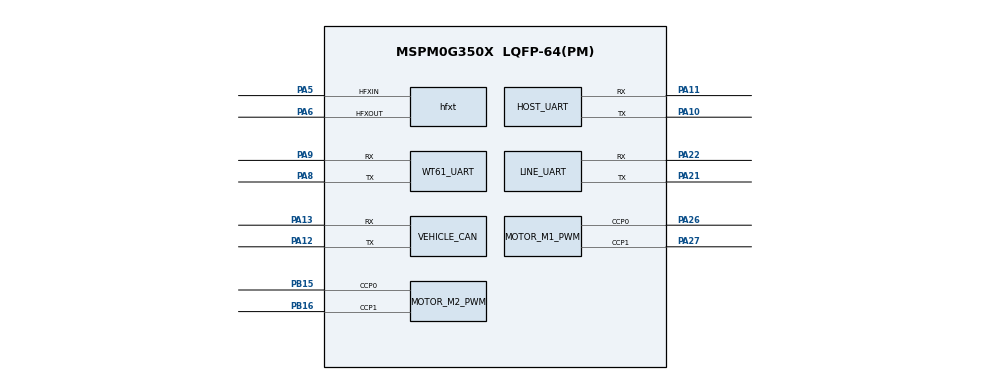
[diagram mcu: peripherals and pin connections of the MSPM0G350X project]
/**
 * MSPM0G3507 project pin/peripheral configuration (v0.3.0 - CAN加速度版)
 *
 * SysConfig 统一管理两路电机：
 *   M1 = TIMG7, PA26/PA27
 *   M2 = TIMG8, PB15/PB16
 * 避免第二路手写寄存器初始化与 SDK/SysConfig 生成配置不一致。
 * 两路编码器 (PB0-PB3) 由 SysConfig 配置成双边沿 GPIO 中断输入，
 * 避免主循环轮询速度不稳定时漏计高速脉冲。
 * CANFD0工作在经典CAN模式：PA12(TX)/PA13(RX)，500 kbps。
 * CANCLK使用核心板PA5/PA6上的40 MHz外部晶振，CPU仍保持32 MHz。
 *
 * @cliArgs --device "MSPM0G350X" --part "Default" --package "LQFP-64(PM)" --product "mspm0_sdk@2.11.00.07"
 * @versions {"tool":"1.26.2+4477"}
 */

const GPIO       = scripting.addModule("/ti/driverlib/GPIO", {}, false);
const BUZZER     = GPIO.addInstance();
const SPEED_KEY  = GPIO.addInstance();
const MODE_KEY   = GPIO.addInstance();
const LCD        = GPIO.addInstance();
const ENCODER_IO = GPIO.addInstance();
const UART       = scripting.addModule("/ti/driverlib/UART", {}, false);
const HOST_UART  = UART.addInstance();
const WT61_UART  = UART.addInstance();
const LINE_UART  = UART.addInstance();
const MCAN       = scripting.addModule("/ti/driverlib/MCAN", {}, false);
const VEHICLE_CAN = MCAN.addInstance();
const PWM        = scripting.addModule("/ti/driverlib/PWM", {}, false);
const MOTOR_M1_PWM = PWM.addInstance();
const MOTOR_M2_PWM = PWM.addInstance();
const SYSCTL     = scripting.addModule("/ti/driverlib/SYSCTL");
const Board      = scripting.addModule("/ti/driverlib/Board", {}, false);

/*
 * 天猛星核心板40 MHz外部晶振仅供HFCLK/CANCLK使用。
 * MCLK仍使用32 MHz SYSOSC，因此现有PWM周期和软件延时基准不改变。
 */
const hfxMux = system.clockTree["EXHFMUX"];
hfxMux.inputSelect = "EXHFMUX_XTAL";
const hfxExt = system.clockTree["HFCLKEXT"];
hfxExt.inputFreq = 40;
const hfxt = system.clockTree["HFXT"];
hfxt.enable = true;
hfxt.HFXTStartup = 10;
hfxt.HFCLKMonitor = true;
hfxt.inputFreq = 40;
hfxt.peripheral.$assign = "SYSCTL";
hfxt.peripheral.hfxInPin.$assign = "PA5";
hfxt.peripheral.hfxOutPin.$assign = "PA6";

/* Optional buzzer already present on the core board. */
BUZZER.port                                  = "PORTA";
BUZZER.$name                                 = "BUZZER";
BUZZER.associatedPins[0].assignedPin         = "7";
BUZZER.associatedPins[0].assignedPortSegment = "Lower";
BUZZER.associatedPins[0].$name               = "PIN";

/*
 * 天猛星核心板板载按键 = PB21，低电平按下。
 * 扩展板 KEY1/PB12 = 单圈/无限巡线模式切换，低电平按下。
 * 注意：扩展板原理图把 PB21 同时引出为 IMU_CS_A；使用板载按键时，
 * 不得让外接 IMU 在该网络上主动驱动电平。
 * 使用内部上拉并由主循环软件消抖，避免人机按键中断干扰编码器 GROUP1 ISR。
 */
SPEED_KEY.port = "PORTB";
SPEED_KEY.$name = "SPEED_KEY";
SPEED_KEY.associatedPins[0].$name = "BUTTON";
SPEED_KEY.associatedPins[0].direction = "INPUT";
SPEED_KEY.associatedPins[0].internalResistor = "PULL_UP";
SPEED_KEY.associatedPins[0].assignedPin = "21";

MODE_KEY.port = "PORTB";
MODE_KEY.$name = "MODE_KEY";
MODE_KEY.associatedPins[0].$name = "MODE_BUTTON";
MODE_KEY.associatedPins[0].direction = "INPUT";
MODE_KEY.associatedPins[0].internalResistor = "PULL_UP";
MODE_KEY.associatedPins[0].assignedPin = "12";

/* ST7735软件SPI；BLK已直接接3.3V，不再占用MCU GPIO。 */
LCD.port = "PORTB";
LCD.$name = "LCD";
LCD.associatedPins.create(5);
LCD.associatedPins[0].$name = "SCLK";
LCD.associatedPins[0].assignedPin = "9";
LCD.associatedPins[1].$name = "MOSI";
LCD.associatedPins[1].assignedPin = "8";
LCD.associatedPins[2].$name = "CS";
LCD.associatedPins[2].initialValue = "SET";
LCD.associatedPins[2].assignedPin = "14";
LCD.associatedPins[3].$name = "DC";
LCD.associatedPins[3].initialValue = "SET";
LCD.associatedPins[3].assignedPin = "11";
LCD.associatedPins[4].$name = "RST";
LCD.associatedPins[4].initialValue = "SET";
LCD.associatedPins[4].assignedPin = "10";

/*
 * N20 双路正交编码器。
 *
 * A、B 两相都在上升沿和下降沿触发中断，因此软件解码为 x4 倍频。
 * 驱动只在 GROUP1_IRQHandler 中读取一次 GPIOB 快照和更新计数；
 * RPM 计算、VOFA 发送等耗时工作仍放在主循环。
 */
ENCODER_IO.port = "PORTB";
ENCODER_IO.$name = "ENCODER_IO";
ENCODER_IO.associatedPins.create(4);
ENCODER_IO.associatedPins[0].$name = "ENC_M1_A";
ENCODER_IO.associatedPins[0].direction = "INPUT";
ENCODER_IO.associatedPins[0].interruptEn = true;
ENCODER_IO.associatedPins[0].polarity = "RISE_FALL";
ENCODER_IO.associatedPins[0].assignedPin = "0";
ENCODER_IO.associatedPins[1].$name = "ENC_M1_B";
ENCODER_IO.associatedPins[1].direction = "INPUT";
ENCODER_IO.associatedPins[1].interruptEn = true;
ENCODER_IO.associatedPins[1].polarity = "RISE_FALL";
ENCODER_IO.associatedPins[1].assignedPin = "1";
ENCODER_IO.associatedPins[2].$name = "ENC_M2_A";
ENCODER_IO.associatedPins[2].direction = "INPUT";
ENCODER_IO.associatedPins[2].interruptEn = true;
ENCODER_IO.associatedPins[2].polarity = "RISE_FALL";
ENCODER_IO.associatedPins[2].assignedPin = "2";
ENCODER_IO.associatedPins[3].$name = "ENC_M2_B";
ENCODER_IO.associatedPins[3].direction = "INPUT";
ENCODER_IO.associatedPins[3].interruptEn = true;
ENCODER_IO.associatedPins[3].polarity = "RISE_FALL";
ENCODER_IO.associatedPins[3].assignedPin = "3";

/*
 * 无线串口/板载CH343：UART0，PA10(TX)/PA11(RX)。
 * VOFA发送使用DMA_CH0；最终波特率和帧格式由BSP_Uart_Init()按照
 * project_config.h重新应用。这里的921600是SysConfig生成代码的初始值。
 */
HOST_UART.$name = "HOST_UART";
HOST_UART.profile = "CONFIG_PROFILE_1";
HOST_UART.enableInternalLoopback = false;
HOST_UART.targetBaudRate = 921600;
HOST_UART.enableFIFO = true;
HOST_UART.txFifoThreshold = "DL_UART_TX_FIFO_LEVEL_ONE_ENTRY";
HOST_UART.enabledInterrupts = ["DMA_DONE_TX"];
HOST_UART.enabledDMATXTriggers = "DL_UART_DMA_INTERRUPT_TX";
HOST_UART.enableDMATX = true;
HOST_UART.peripheral.$assign = "UART0";
HOST_UART.peripheral.txPin.$assign = "PA10";
HOST_UART.peripheral.rxPin.$assign = "PA11";
HOST_UART.DMA_CHANNEL_TX.peripheral.$assign = "DMA_CH0";
HOST_UART.DMA_CHANNEL_TX.addressMode = "b2f";
HOST_UART.DMA_CHANNEL_TX.srcIncDec = "INCREMENT";
HOST_UART.DMA_CHANNEL_TX.dstLength = "BYTE";
HOST_UART.DMA_CHANNEL_TX.srcLength = "BYTE";

/*
 * WT61TTL：UART1，实物已通过上位机配置为 115200-8-N-1，
 * PA8(TX) / PA9(RX)。
 * 接收使用 DMA_CH1，每收到一个11字节标准帧才进入一次中断。
 *
 * PA8/PA9 和 PB6/PB7 都属于 UART1，不能同时连接原蓝牙 UART1；
 * 当前配置以 WT61TTL 为准。
 */
WT61_UART.$name = "WT61_UART";
WT61_UART.profile = "CONFIG_PROFILE_1";
WT61_UART.enableInternalLoopback = false;
WT61_UART.targetBaudRate = 115200;
WT61_UART.enableFIFO = true;
WT61_UART.rxFifoThreshold = "DL_UART_RX_FIFO_LEVEL_ONE_ENTRY";
WT61_UART.enabledInterrupts = ["DMA_DONE_RX"];
WT61_UART.enabledDMARXTriggers = "DL_UART_DMA_INTERRUPT_RX";
WT61_UART.enableDMARX = true;
WT61_UART.peripheral.$assign = "UART1";
WT61_UART.peripheral.txPin.$assign = "PA8";
WT61_UART.peripheral.rxPin.$assign = "PA9";
WT61_UART.DMA_CHANNEL_RX.peripheral.$assign = "DMA_CH1";
WT61_UART.DMA_CHANNEL_RX.addressMode = "f2b";
WT61_UART.DMA_CHANNEL_RX.dstIncDec = "INCREMENT";
WT61_UART.DMA_CHANNEL_RX.dstLength = "BYTE";
WT61_UART.DMA_CHANNEL_RX.srcLength = "BYTE";

/*
 * Hiwonder 8路红外巡线模块：UART2，PA21(TX)/PA22(RX)，115200-8-N-1。
 * 模块TX接PA22，模块RX接PA21。RX/TX分别使用DMA_CH2/DMA_CH3，
 * 不改变VOFA的DMA_CH0和WT61的DMA_CH1。
 */
LINE_UART.$name = "LINE_UART";
LINE_UART.profile = "CONFIG_PROFILE_1";
LINE_UART.enableInternalLoopback = false;
LINE_UART.targetBaudRate = 115200;
LINE_UART.enableFIFO = true;
LINE_UART.rxFifoThreshold = "DL_UART_RX_FIFO_LEVEL_ONE_ENTRY";
LINE_UART.txFifoThreshold = "DL_UART_TX_FIFO_LEVEL_ONE_ENTRY";
LINE_UART.enabledInterrupts = ["DMA_DONE_RX", "DMA_DONE_TX"];
LINE_UART.enabledDMARXTriggers = "DL_UART_DMA_INTERRUPT_RX";
LINE_UART.enabledDMATXTriggers = "DL_UART_DMA_INTERRUPT_TX";
LINE_UART.enableDMARX = true;
LINE_UART.enableDMATX = true;
LINE_UART.peripheral.$assign = "UART2";
LINE_UART.peripheral.txPin.$assign = "PA21";
LINE_UART.peripheral.rxPin.$assign = "PA22";
LINE_UART.DMA_CHANNEL_RX.peripheral.$assign = "DMA_CH2";
LINE_UART.DMA_CHANNEL_RX.addressMode = "f2b";
LINE_UART.DMA_CHANNEL_RX.dstIncDec = "INCREMENT";
LINE_UART.DMA_CHANNEL_RX.dstLength = "BYTE";
LINE_UART.DMA_CHANNEL_RX.srcLength = "BYTE";
LINE_UART.DMA_CHANNEL_TX.peripheral.$assign = "DMA_CH3";
LINE_UART.DMA_CHANNEL_TX.addressMode = "b2f";
LINE_UART.DMA_CHANNEL_TX.srcIncDec = "UNCHANGED";
LINE_UART.DMA_CHANNEL_TX.dstLength = "BYTE";
LINE_UART.DMA_CHANNEL_TX.srcLength = "BYTE";

/*
 * 车体板到钢珠控制板使用经典CAN，降低对收发器和对端配置的要求。
 * 禁止自动重传(DAR=true)：加速度是实时量，偶发丢帧时下一拍发送新数据，
 * 不让总线恢复后继续发送已经过期的旧样本。
 * 当前只发送，因此仅分配1个专用Tx Buffer，不分配Rx FIFO和滤波器。
 */
VEHICLE_CAN.$name                    = "VEHICLE_CAN";
VEHICLE_CAN.fdMode                   = false;
VEHICLE_CAN.darEnable                = true;
VEHICLE_CAN.desiredNomRate           = 500;
VEHICLE_CAN.desiredDataRate          = 0;
VEHICLE_CAN.additionalCoreConfig     = true;
VEHICLE_CAN.rrfe                     = true;
VEHICLE_CAN.rrfs                     = true;
VEHICLE_CAN.anfe                     = "1";
VEHICLE_CAN.anfs                     = "1";
VEHICLE_CAN.lss                      = 0;
VEHICLE_CAN.lse                      = 0;
VEHICLE_CAN.txStartAddr              = 0;
VEHICLE_CAN.txBufNum                 = 1;
VEHICLE_CAN.rxFIFO0startAddr         = 0;
VEHICLE_CAN.rxFIFO1startAddr         = 0;
VEHICLE_CAN.rxBufStartAddr           = 0;
VEHICLE_CAN.rxFIFO0size              = 0;
VEHICLE_CAN.rxFIFO1size              = 0;
VEHICLE_CAN.flesa                    = 0;
VEHICLE_CAN.txEventFIFOWaterMark     = 0;
VEHICLE_CAN.overrideRetention        = true;
VEHICLE_CAN.peripheral.$assign       = "CANFD0";
VEHICLE_CAN.peripheral.rxPin.$assign = "PA13";
VEHICLE_CAN.peripheral.txPin.$assign = "PA12";

/*
 * M1 DRV8871 IN1/IN2: TIMG7 CCP0/CCP1 at 20 kHz
 * 严格按照立创天猛星 wiki 手册：PA26, PA27
 * CPUCLK = 32 MHz, timerCount = 32 MHz / 20 kHz = 1600.
 *
 * M2 DRV8871 BIN1/BIN2: TIMG8 CCP0/CCP1 at 20 kHz
 * 原理图网络为 PB15 / PB16。
 */
MOTOR_M1_PWM.$name = "MOTOR_M1_PWM";
MOTOR_M1_PWM.timerCount = 1600;
MOTOR_M1_PWM.peripheral.$assign = "TIMG7";
MOTOR_M1_PWM.peripheral.ccp0Pin.$assign = "PA26";
MOTOR_M1_PWM.peripheral.ccp1Pin.$assign = "PA27";
MOTOR_M1_PWM.PWM_CHANNEL_0.$name = "MOTOR_M1_IN1";
MOTOR_M1_PWM.PWM_CHANNEL_0.dutyCycle = 0;
MOTOR_M1_PWM.PWM_CHANNEL_1.$name = "MOTOR_M1_IN2";
MOTOR_M1_PWM.PWM_CHANNEL_1.dutyCycle = 0;

MOTOR_M2_PWM.$name = "MOTOR_M2_PWM";
MOTOR_M2_PWM.timerCount = 1600;
MOTOR_M2_PWM.peripheral.$assign = "TIMG8";
MOTOR_M2_PWM.peripheral.ccp0Pin.$assign = "PB15";
MOTOR_M2_PWM.peripheral.ccp1Pin.$assign = "PB16";
MOTOR_M2_PWM.PWM_CHANNEL_0.$name = "MOTOR_M2_IN1";
MOTOR_M2_PWM.PWM_CHANNEL_0.dutyCycle = 0;
MOTOR_M2_PWM.PWM_CHANNEL_1.$name = "MOTOR_M2_IN2";
MOTOR_M2_PWM.PWM_CHANNEL_1.dutyCycle = 0;

/* 保持32 MHz默认MCLK，只额外启用40 MHz HFXT作为CANCLK。 */
SYSCTL.forceDefaultClkConfig = true;
SYSCTL.CANCLKSource = "HFCLK";
SYSCTL.useHFCLK_Manual = true;
SYSCTL.HFCLKSource = "HFXT";
SYSCTL.HFCLK_Freq = 40000000;
SYSCTL.HFCLKMonitor = true;
SYSCTL.HFXTStartup = 10;
SYSCTL.clockTreeEn = true;

/* Lock the chosen solution so future SysConfig versions do not move pins. */
BUZZER.associatedPins[0].pin.$suggestSolution = "PA7";
SPEED_KEY.associatedPins[0].pin.$suggestSolution = "PB21";
MODE_KEY.associatedPins[0].pin.$suggestSolution = "PB12";
LCD.associatedPins[0].pin.$suggestSolution = "PB9";
LCD.associatedPins[1].pin.$suggestSolution = "PB8";
LCD.associatedPins[2].pin.$suggestSolution = "PB14";
LCD.associatedPins[3].pin.$suggestSolution = "PB11";
LCD.associatedPins[4].pin.$suggestSolution = "PB10";
ENCODER_IO.associatedPins[0].pin.$suggestSolution = "PB0";
ENCODER_IO.associatedPins[1].pin.$suggestSolution = "PB1";
ENCODER_IO.associatedPins[2].pin.$suggestSolution = "PB2";
ENCODER_IO.associatedPins[3].pin.$suggestSolution = "PB3";
WT61_UART.peripheral.txPin.$suggestSolution = "PA8";
WT61_UART.peripheral.rxPin.$suggestSolution = "PA9";
LINE_UART.peripheral.txPin.$suggestSolution = "PA21";
LINE_UART.peripheral.rxPin.$suggestSolution = "PA22";
VEHICLE_CAN.peripheral.txPin.$suggestSolution = "PA12";
VEHICLE_CAN.peripheral.rxPin.$suggestSolution = "PA13";
MOTOR_M1_PWM.peripheral.ccp0Pin.$suggestSolution = "PA26";
MOTOR_M1_PWM.peripheral.ccp1Pin.$suggestSolution = "PA27";
MOTOR_M2_PWM.peripheral.ccp0Pin.$suggestSolution = "PB15";
MOTOR_M2_PWM.peripheral.ccp1Pin.$suggestSolution = "PB16";
Board.peripheral.$suggestSolution = "DEBUGSS";
Board.peripheral.swclkPin.$suggestSolution = "PA20";
Board.peripheral.swdioPin.$suggestSolution = "PA19";
